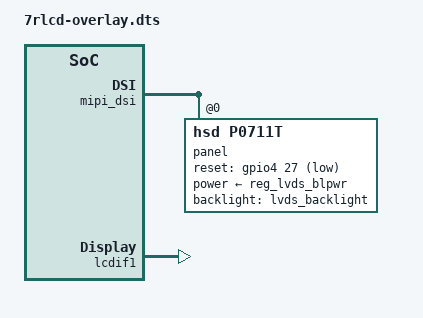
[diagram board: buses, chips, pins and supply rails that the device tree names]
// SPDX-License-Identifier: (GPL-2.0+ OR MIT)
/*
 * Copyright 2023 ADLINK Technology Corp.
 *
 * Author: Po Cheng <po.cheng@adlinktech.com>
 */

/dts-v1/;
/plugin/;

/ {
	fragment@0 {
		target-path = "/";
		__overlay__ {
			lvds_backlight {
				status = "okay";
			};
		};
	};

	fragment@1 {
		target = <&mipi_dsi>;
		__overlay__ {
			#address-cells = <1>;
			#size-cells = <0>;
			status = "okay";
			panel@0 {
				compatible = "hsd,p0711t";
				reg = <0>;
				power-supply = <&reg_lvds_blpwr>;
				reset-gpios = <&gpio4 27 1>; /* GPIO_ACTIVE_LOW */
				backlight = <&lvds_backlight>;
				/* enum mipi_dsi_pixel_format { MIPI_DSI_FMT_RGB888, MIPI_DSI_FMT_RGB666, MIPI_DSI_FMT_RGB666_PACKED, MIPI_DSI_FMT_RGB565, }; */
				dsi-format = <2>;
				flip-horizontal;
				flip-vertical;
				status = "okay";
			};
		};
	};

	fragment@2 {
		target = <&lcdif1>;
		__overlay__ {
			status = "okay";
		};
	};
};

